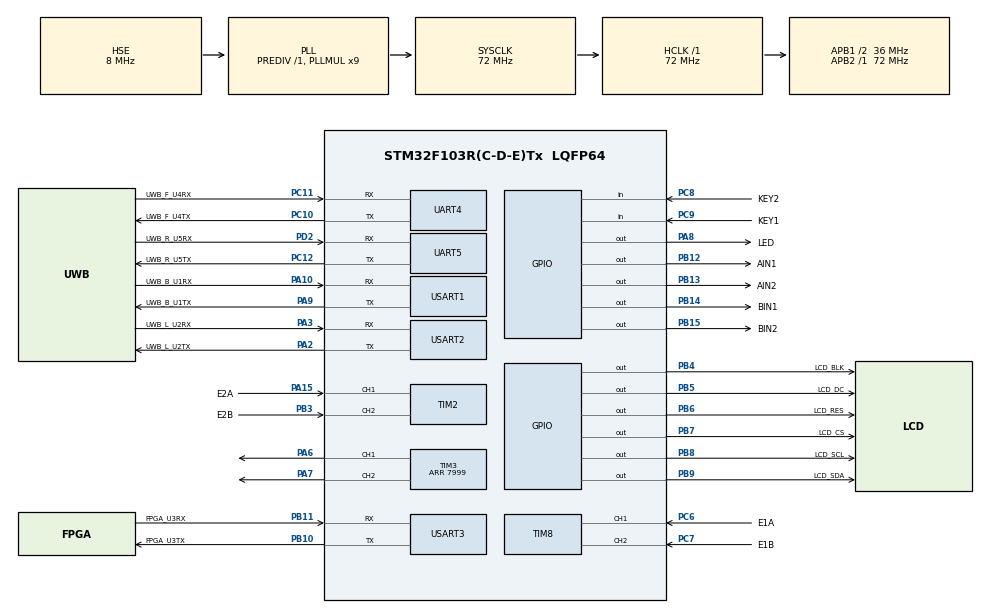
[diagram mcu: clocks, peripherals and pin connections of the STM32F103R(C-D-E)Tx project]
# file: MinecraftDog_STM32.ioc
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Dma.Request0=USART3_RX
Dma.Request1=USART3_TX
Dma.USART3_RX.0.Direction=DMA_PERIPH_TO_MEMORY
Dma.USART3_RX.0.Instance=DMA1_Channel3
Dma.USART3_RX.0.MemDataAlignment=DMA_MDATAALIGN_BYTE
Dma.USART3_RX.0.MemInc=DMA_MINC_ENABLE
Dma.USART3_RX.0.Mode=DMA_CIRCULAR
Dma.USART3_RX.0.PeriphDataAlignment=DMA_PDATAALIGN_BYTE
Dma.USART3_RX.0.PeriphInc=DMA_PINC_DISABLE
Dma.USART3_RX.0.Priority=DMA_PRIORITY_HIGH
Dma.USART3_TX.1.Direction=DMA_MEMORY_TO_PERIPH
Dma.USART3_TX.1.Instance=DMA1_Channel2
Dma.USART3_TX.1.MemDataAlignment=DMA_MDATAALIGN_BYTE
Dma.USART3_TX.1.MemInc=DMA_MINC_ENABLE
Dma.USART3_TX.1.Mode=DMA_NORMAL
Dma.USART3_TX.1.PeriphDataAlignment=DMA_PDATAALIGN_BYTE
Dma.USART3_TX.1.PeriphInc=DMA_PINC_DISABLE
Dma.USART3_TX.1.Priority=DMA_PRIORITY_LOW
Mcu.Family=STM32F1
Mcu.Name=STM32F103R(C-D-E)Tx
Mcu.Package=LQFP64
NVIC.DMA1_Channel2_IRQn=true\:0\:0\:false\:false\:true\:false\:true\:true
NVIC.DMA1_Channel3_IRQn=true\:0\:0\:false\:false\:true\:false\:true\:true
NVIC.PriorityGroup=NVIC_PRIORITYGROUP_4
NVIC.UART4_IRQn=true\:0\:0\:false\:false\:true\:true\:true\:true
NVIC.UART5_IRQn=true\:0\:0\:false\:false\:true\:true\:true\:true
NVIC.USART1_IRQn=true\:0\:0\:false\:false\:true\:true\:true\:true
NVIC.USART2_IRQn=true\:0\:0\:false\:false\:true\:true\:true\:true
NVIC.USART3_IRQn=true\:0\:0\:false\:false\:true\:false\:true\:true
PA10.GPIO_Label=UWB_B_U1RX
PA10.GPIO_PuPd=GPIO_PULLUP
PA10.Mode=Asynchronous
PA10.Signal=USART1_RX
PA13.Mode=Serial_Wire
PA13.Signal=SYS_JTMS-SWDIO
PA14.Mode=Serial_Wire
PA14.Signal=SYS_JTCK-SWCLK
PA15.GPIO_Label=E2A
PA15.Signal=S_TIM2_CH1_ETR
PA2.GPIO_Label=UWB_L_U2TX
PA2.Mode=Asynchronous
PA2.Signal=USART2_TX
PA3.GPIO_Label=UWB_L_U2RX
PA3.GPIO_PuPd=GPIO_PULLUP
PA3.Mode=Asynchronous
PA3.Signal=USART2_RX
PA6.Signal=S_TIM3_CH1
PA7.Signal=S_TIM3_CH2
PA8.GPIO_Label=LED
PA8.Signal=GPIO_Output
PA9.GPIO_Label=UWB_B_U1TX
PA9.Mode=Asynchronous
PA9.Signal=USART1_TX
PB10.GPIO_Label=FPGA_U3TX
PB10.Mode=Asynchronous
PB10.Signal=USART3_TX
PB11.GPIO_Label=FPGA_U3RX
PB11.GPIO_PuPd=GPIO_PULLUP
PB11.Mode=Asynchronous
PB11.Signal=USART3_RX
PB12.GPIO_Label=AIN1
PB12.GPIO_ModeDefaultOutputPP=GPIO_MODE_OUTPUT_PP
PB12.GPIO_PuPd=GPIO_NOPULL
PB12.Signal=GPIO_Output
PB13.GPIO_Label=AIN2
PB13.Signal=GPIO_Output
PB14.GPIO_Label=BIN1
PB14.Signal=GPIO_Output
PB15.GPIO_Label=BIN2
PB15.Signal=GPIO_Output
PB3.GPIO_Label=E2B
PB3.Signal=S_TIM2_CH2
PB4.GPIO_Label=LCD_BLK
PB4.Signal=GPIO_Output
PB5.GPIO_Label=LCD_DC
PB5.Signal=GPIO_Output
PB6.GPIO_Label=LCD_RES
PB6.Signal=GPIO_Output
PB7.GPIO_Label=LCD_CS
PB7.Signal=GPIO_Output
PB8.GPIO_Label=LCD_SCL
PB8.Signal=GPIO_Output
PB9.GPIO_Label=LCD_SDA
PB9.Signal=GPIO_Output
PC10.GPIO_Label=UWB_F_U4TX
PC10.Mode=Asynchronous
PC10.Signal=UART4_TX
PC11.GPIO_Label=UWB_F_U4RX
PC11.GPIO_PuPd=GPIO_PULLUP
PC11.Mode=Asynchronous
PC11.Signal=UART4_RX
PC12.GPIO_Label=UWB_R_U5TX
PC12.Mode=Asynchronous
PC12.Signal=UART5_TX
PC6.GPIO_Label=E1A
PC6.Signal=S_TIM8_CH1
PC7.GPIO_Label=E1B
PC7.Signal=S_TIM8_CH2
PC8.GPIO_Label=KEY2
PC8.GPIO_PuPd=GPIO_PULLUP
PC8.Signal=GPIO_Input
PC9.GPIO_Label=KEY1
PC9.GPIO_PuPd=GPIO_PULLUP
PC9.Signal=GPIO_Input
PD0-OSC_IN.Mode=HSE-External-Oscillator
PD0-OSC_IN.Signal=RCC_OSC_IN
PD1-OSC_OUT.Mode=HSE-External-Oscillator
PD1-OSC_OUT.Signal=RCC_OSC_OUT
PD2.GPIO_Label=UWB_R_U5RX
PD2.GPIO_PuPd=GPIO_PULLUP
PD2.Mode=Asynchronous
PD2.Signal=UART5_RX
ProjectManager.HeapSize=0x200
ProjectManager.StackSize=0x400
ProjectManager.TargetToolchain=STM32CubeIDE
RCC.AHBFreq_Value=72000000
RCC.APB1CLKDivider=RCC_HCLK_DIV2
RCC.APB1Freq_Value=36000000
RCC.APB1TimFreq_Value=72000000
RCC.APB2Freq_Value=72000000
RCC.APB2TimFreq_Value=72000000
RCC.HCLKFreq_Value=72000000
RCC.PLLMUL=RCC_PLL_MUL9
RCC.PLLSourceVirtual=RCC_PLLSOURCE_HSE
RCC.SYSCLKFreq_VALUE=72000000
RCC.SYSCLKSource=RCC_SYSCLKSOURCE_PLLCLK
RCC.USBFreq_Value=72000000
SH.S_TIM2_CH1_ETR.0=TIM2_CH1,Encoder_Interface
SH.S_TIM2_CH2.0=TIM2_CH2,Encoder_Interface
SH.S_TIM3_CH1.0=TIM3_CH1,PWM Generation1 CH1
SH.S_TIM3_CH2.0=TIM3_CH2,PWM Generation2 CH2
SH.S_TIM8_CH1.0=TIM8_CH1,Encoder_Interface
SH.S_TIM8_CH2.0=TIM8_CH2,Encoder_Interface
TIM2.EncoderMode=TIM_ENCODERMODE_TI12
TIM2.IC1Filter=10
TIM2.IC2Filter=10
TIM3.AutoReloadPreload=TIM_AUTORELOAD_PRELOAD_ENABLE
TIM3.Channel-PWM\ Generation1\ CH1=TIM_CHANNEL_1
TIM3.Channel-PWM\ Generation2\ CH2=TIM_CHANNEL_2
TIM3.Period=7999
TIM8.EncoderMode=TIM_ENCODERMODE_TI12
TIM8.IC1Filter=10
TIM8.IC2Filter=10
UART4.VirtualMode=Asynchronous
UART5.VirtualMode=Asynchronous
USART1.VirtualMode=VM_ASYNC
USART2.VirtualMode=VM_ASYNC
USART3.VirtualMode=VM_ASYNC
VP_TIM3_VS_ClockSourceINT.Mode=Internal
board=custom

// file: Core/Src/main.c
/* USER CODE BEGIN Header */
/**
  ******************************************************************************
  * @file           : main.c
  * @brief          : Main program body
  ******************************************************************************
  * @attention
  *
  * Copyright (c) 2026 STMicroelectronics.
  * All rights reserved.
  *
  * This software is licensed under terms that can be found in the LICENSE file
  * in the root directory of this software component.
  * If no LICENSE file comes with this software, it is provided AS-IS.
  *
  ******************************************************************************
  */
/* USER CODE END Header */
#include "main.h"
#include "dma.h"
#include "tim.h"
#include "usart.h"
#include "gpio.h"

/* USER CODE BEGIN Includes */
#include "AllHeader.h"
/* USER CODE END Includes */

void SystemClock_Config(void);

int main(void)
{

  /* MCU Configuration--------------------------------------------------------*/

  /* Reset of all peripherals, Initializes the Flash interface and the Systick. */
  HAL_Init();

  /* Configure the system clock */
  SystemClock_Config();

  /* Initialize all configured peripherals */
  MX_GPIO_Init();
  MX_DMA_Init();
  MX_USART3_UART_Init();
  MX_TIM2_Init();
  MX_TIM3_Init();
  MX_TIM8_Init();
  MX_UART4_Init();
  MX_UART5_Init();
  MX_USART2_UART_Init();
  MX_USART1_UART_Init();
  /* USER CODE BEGIN 2 */
  bsp_init();
  /* USER CODE END 2 */

  /* Infinite loop */
  while (1)
  {

    /* USER CODE BEGIN 3 */
    Scheduler_Run();
  }
  /* USER CODE END 3 */
}

void SystemClock_Config(void)
{
  RCC_OscInitTypeDef RCC_OscInitStruct = {0};
  RCC_ClkInitTypeDef RCC_ClkInitStruct = {0};

  /** Initializes the RCC Oscillators according to the specified parameters
  * in the RCC_OscInitTypeDef structure.
  */
  RCC_OscInitStruct.OscillatorType = RCC_OSCILLATORTYPE_HSE;
  RCC_OscInitStruct.HSEState = RCC_HSE_ON;
  RCC_OscInitStruct.HSEPredivValue = RCC_HSE_PREDIV_DIV1;
  RCC_OscInitStruct.HSIState = RCC_HSI_ON;
  RCC_OscInitStruct.PLL.PLLState = RCC_PLL_ON;
  RCC_OscInitStruct.PLL.PLLSource = RCC_PLLSOURCE_HSE;
  RCC_OscInitStruct.PLL.PLLMUL = RCC_PLL_MUL9;
  if (HAL_RCC_OscConfig(&RCC_OscInitStruct) != HAL_OK)
  {
    Error_Handler();
  }

  /** Initializes the CPU, AHB and APB buses clocks
  */
  RCC_ClkInitStruct.ClockType = RCC_CLOCKTYPE_HCLK|RCC_CLOCKTYPE_SYSCLK
                              |RCC_CLOCKTYPE_PCLK1|RCC_CLOCKTYPE_PCLK2;
  RCC_ClkInitStruct.SYSCLKSource = RCC_SYSCLKSOURCE_PLLCLK;
  RCC_ClkInitStruct.AHBCLKDivider = RCC_SYSCLK_DIV1;
  RCC_ClkInitStruct.APB1CLKDivider = RCC_HCLK_DIV2;
  RCC_ClkInitStruct.APB2CLKDivider = RCC_HCLK_DIV1;

  if (HAL_RCC_ClockConfig(&RCC_ClkInitStruct, FLASH_LATENCY_2) != HAL_OK)
  {
    Error_Handler();
  }
}

void Error_Handler(void)
{
  __disable_irq();
  while (1)
  {
  }
}
